# STM32WB55x register map
File version: 1.0
CPU: CM4 r0p1, little endian, 4 interrupt priority bits
Registers are 32-bit, read-write, reset 0x0 unless marked. A register's access mark holds for its fields unless they carry their own. Offsets are from the block's base; [hi:lo] are bit positions; {n}, {i} and the like mark numbered series; 'fields as' and 'values as' point back to an identical list.

## PWR
Base 0x58000400
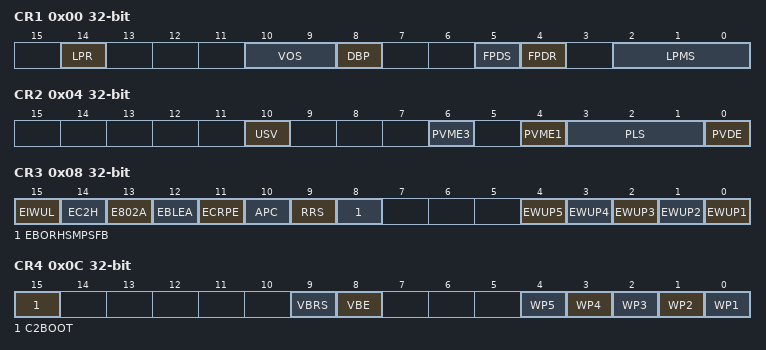
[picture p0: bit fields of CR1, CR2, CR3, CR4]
0x00 CR1
  [14] LPR, [10:9] VOS, [8] DBP, [5] FPDS, [4] FPDR, [2:0] LPMS
0x04 CR2
  [10] USV, [6] PVME3, [4] PVME1, [3:1] PLS, [0] PVDE
0x08 CR3
  [15] EIWUL, [14] EC2H, [13] E802A, [12] EBLEA, [11] ECRPE, [10] APC, [9] RRS, [8] EBORHSMPSFB, [n-1] EWUP{n} (n=1..5)
0x0C CR4
  [15] C2BOOT, [9] VBRS, [8] VBE, [n-1] WP{n} (n=1..5)
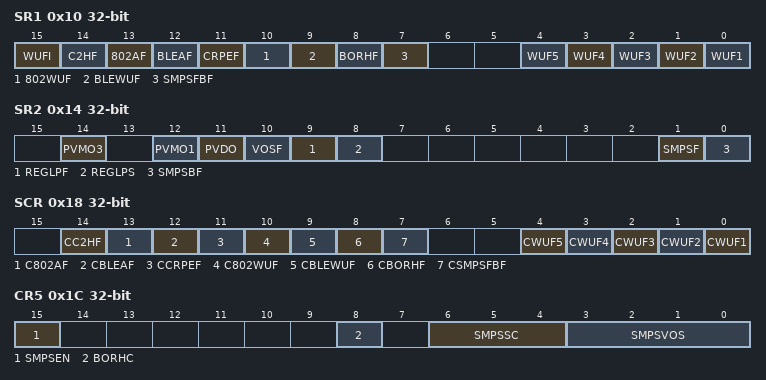
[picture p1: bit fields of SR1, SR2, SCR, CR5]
0x10 SR1
  [15] WUFI, [14] C2HF, [13] 802AF, [12] BLEAF, [11] CRPEF, [10] 802WUF, [9] BLEWUF, [8] BORHF, [7] SMPSFBF, [n-1] WUF{n} (n=1..5)
0x14 SR2
  [14] PVMO3, [12] PVMO1, [11] PVDO, [10] VOSF, [9] REGLPF, [8] REGLPS, [1] SMPSF, [0] SMPSBF
0x18 SCR
  [14] CC2HF, [13] C802AF, [12] CBLEAF, [11] CCRPEF, [10] C802WUF, [9] CBLEWUF, [8] CBORHF, [7] CSMPSFBF, [n-1] CWUF{n} (n=1..5)
0x1C CR5
  [15] SMPSEN, [8] BORHC, [6:4] SMPSSC, [3:0] SMPSVOS
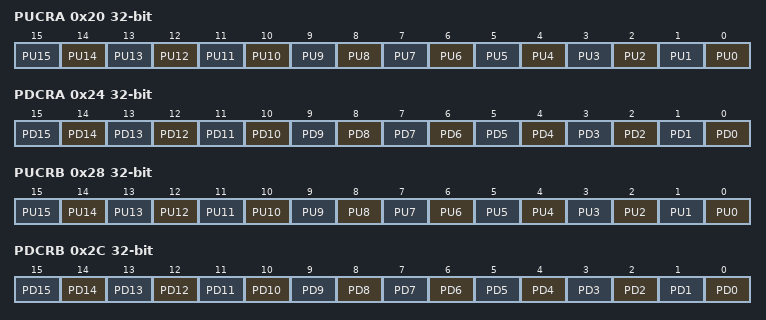
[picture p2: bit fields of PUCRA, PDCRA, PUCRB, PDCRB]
0x20 PUCRA
  [n] PU{n} (n=0..15)
0x24 PDCRA
  [n] PD{n} (n=0..15)
0x28 PUCRB
  [n] PU{n} (n=0..15)
0x2C PDCRB
  [n] PD{n} (n=0..15)
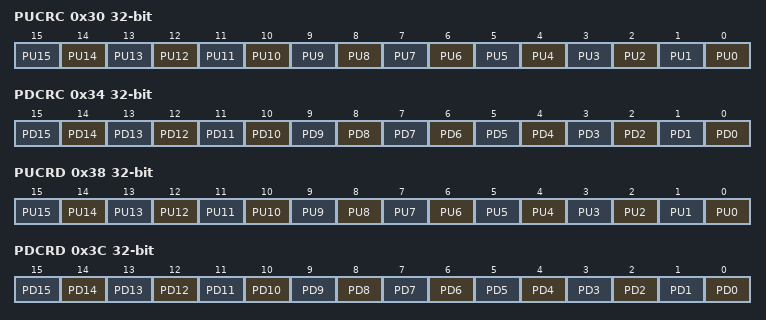
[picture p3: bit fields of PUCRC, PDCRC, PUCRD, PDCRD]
0x30 PUCRC
  [n] PU{n} (n=0..15)
0x34 PDCRC
  [n] PD{n} (n=0..15)
0x38 PUCRD
  [n] PU{n} (n=0..15)
0x3C PDCRD
  [n] PD{n} (n=0..15)
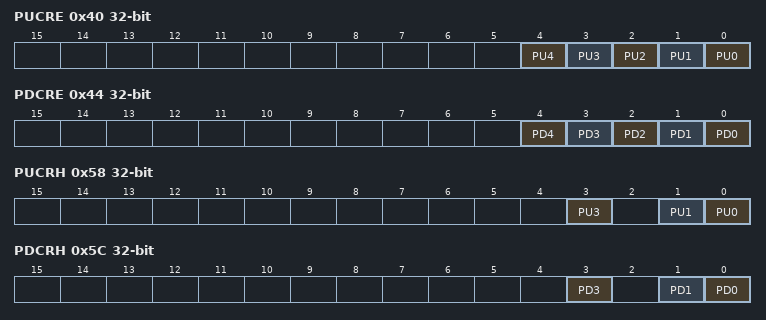
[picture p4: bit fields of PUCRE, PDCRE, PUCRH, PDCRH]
0x40 PUCRE
  [n] PU{n} (n=0..4)
0x44 PDCRE
  [n] PD{n} (n=0..4)
0x58 PUCRH
  [3] PU3, [1] PU1, [0] PU0
0x5C PDCRH
  [3] PD3, [1] PD1, [0] PD0
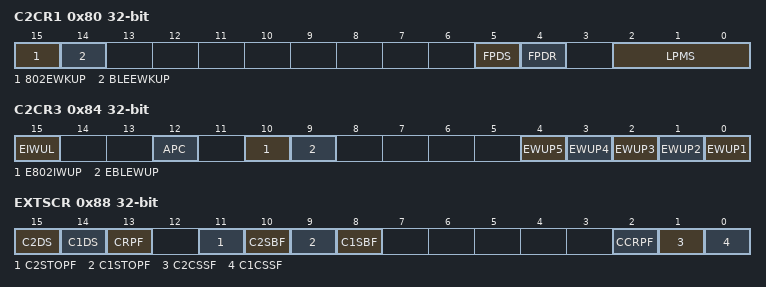
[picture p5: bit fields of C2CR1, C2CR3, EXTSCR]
0x80 C2CR1
  [15] 802EWKUP, [14] BLEEWKUP, [5] FPDS, [4] FPDR, [2:0] LPMS
0x84 C2CR3
  [15] EIWUL, [12] APC, [10] E802IWUP, [9] EBLEWUP, [n-1] EWUP{n} (n=1..5)
0x88 EXTSCR
  [15] C2DS, [14] C1DS, [13] CRPF, [11] C2STOPF, [10] C2SBF, [9] C1STOPF, [8] C1SBF, [2] CCRPF, [1] C2CSSF, [0] C1CSSF

## SAI
Base 0x40015400
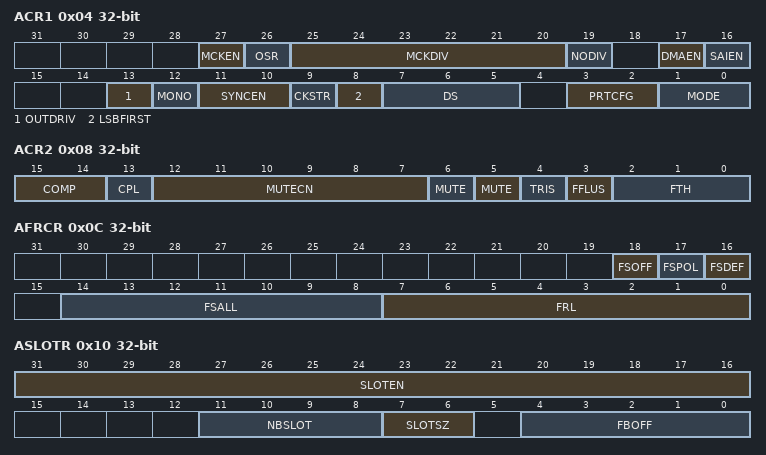
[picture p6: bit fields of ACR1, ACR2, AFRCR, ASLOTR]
0x04 ACR1
  [27] MCKEN, [26] OSR, [25:20] MCKDIV, [19] NODIV, [17] DMAEN, [16] SAIEN, [13] OUTDRIV, [12] MONO, [11:10] SYNCEN, [9] CKSTR, [8] LSBFIRST, [7:5] DS, [3:2] PRTCFG, [1:0] MODE
0x08 ACR2
  [15:14] COMP, [13] CPL, [12:7] MUTECN, [6] MUTE VAL, [5] MUTE, [4] TRIS, [3] FFLUS, [2:0] FTH
0x0C AFRCR
  [18] FSOFF, [17] FSPOL, [16] FSDEF, [14:8] FSALL, [7:0] FRL
0x10 ASLOTR
  [31:16] SLOTEN, [11:8] NBSLOT, [7:6] SLOTSZ, [4:0] FBOFF
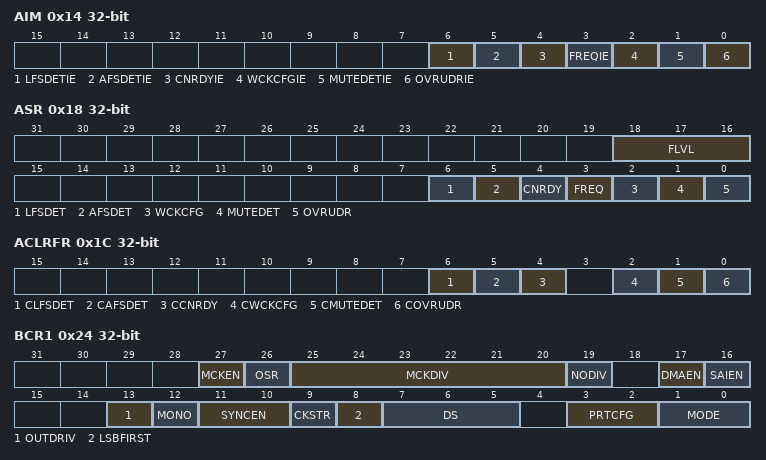
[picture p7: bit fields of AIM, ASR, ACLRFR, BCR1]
0x14 AIM
  [6] LFSDETIE, [5] AFSDETIE, [4] CNRDYIE, [3] FREQIE, [2] WCKCFGIE, [1] MUTEDETIE, [0] OVRUDRIE
0x18 ASR
  [18:16] FLVL, [6] LFSDET, [5] AFSDET, [4] CNRDY, [3] FREQ, [2] WCKCFG, [1] MUTEDET, [0] OVRUDR
0x1C ACLRFR
  [6] CLFSDET, [5] CAFSDET, [4] CCNRDY, [2] CWCKCFG, [1] CMUTEDET, [0] COVRUDR
0x20 ADR
  [31:0] DATA
0x24 BCR1
  fields as ACR1
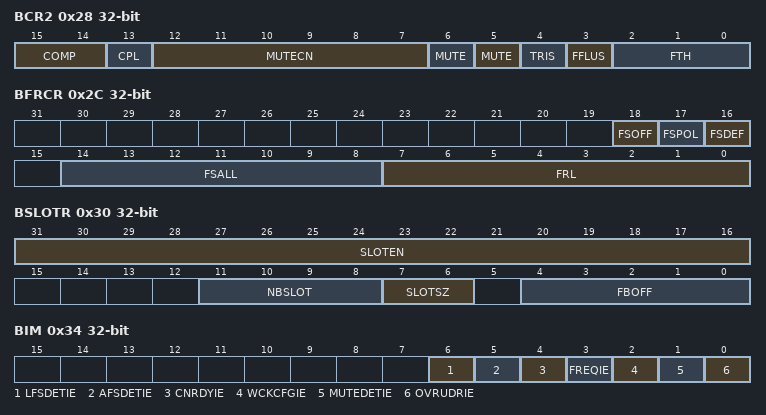
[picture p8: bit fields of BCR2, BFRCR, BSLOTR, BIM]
0x28 BCR2
  fields as ACR2
0x2C BFRCR
  [18] FSOFF, [17] FSPOL, [16] FSDEF, [14:8] FSALL, [7:0] FRL
0x30 BSLOTR
  [31:16] SLOTEN, [11:8] NBSLOT, [7:6] SLOTSZ, [4:0] FBOFF
0x34 BIM
  fields as AIM
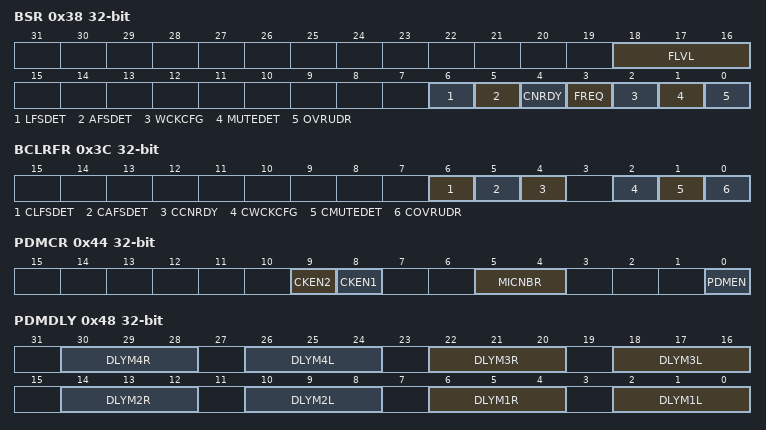
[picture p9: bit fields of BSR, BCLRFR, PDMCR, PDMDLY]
0x38 BSR
  fields as ASR
0x3C BCLRFR
  fields as ACLRFR
0x40 BDR
  [31:0] DATA
0x44 PDMCR
  [9] CKEN2, [8] CKEN1, [5:4] MICNBR, [0] PDMEN
0x48 PDMDLY
  [8n-2:8n-4] DLYM{n}R (n=1..4), [8n-6:8n-8] DLYM{n}L (n=1..4)

## QUADSPI
Base 0xA0001000
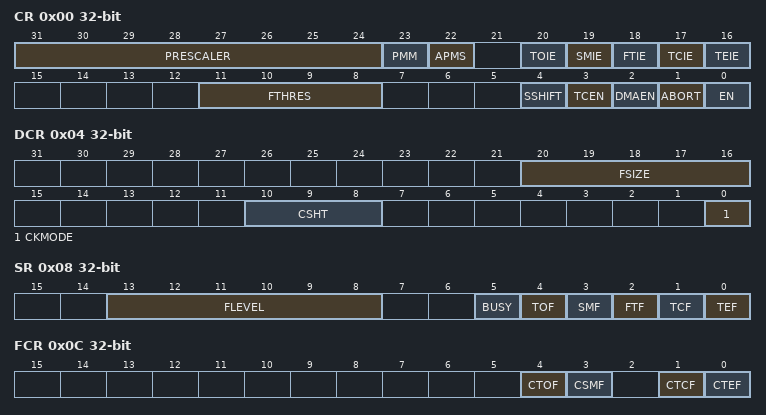
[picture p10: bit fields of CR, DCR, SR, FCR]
0x00 CR
  [31:24] PRESCALER, [23] PMM, [22] APMS, [20] TOIE, [19] SMIE, [18] FTIE, [17] TCIE, [16] TEIE, [11:8] FTHRES, [4] SSHIFT, [3] TCEN, [2] DMAEN, [1] ABORT, [0] EN
0x04 DCR
  [20:16] FSIZE, [10:8] CSHT, [0] CKMODE
0x08 SR
  [13:8] FLEVEL, [5] BUSY, [4] TOF, [3] SMF, [2] FTF, [1] TCF, [0] TEF
0x0C FCR
  [4] CTOF, [3] CSMF, [1] CTCF, [0] CTEF
0x10 DLR
  [31:0] DL
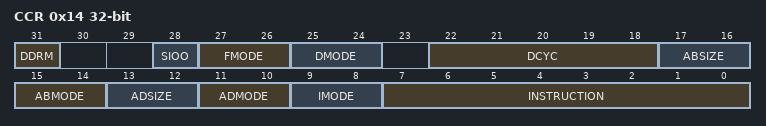
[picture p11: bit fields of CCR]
0x14 CCR
  [31] DDRM, [28] SIOO, [27:26] FMODE, [25:24] DMODE, [22:18] DCYC, [17:16] ABSIZE, [15:14] ABMODE, [13:12] ADSIZE, [11:10] ADMODE, [9:8] IMODE, [7:0] INSTRUCTION
0x18 AR
  [31:0] ADDRESS
0x1C ABR
  [31:0] ALTERNATE
0x20 DR
  [31:0] DATA
0x24 PSMKR
  [31:0] MASK
0x28 PSMAR
  [31:0] MATCH
0x2C PIR
  [15:0] INTERVAL
0x30 LPTR
  [15:0] TIMEOUT

## SYSCFG
Base 0x40010000
0x00 MEMRMP
  [2:0] MEM_MODE
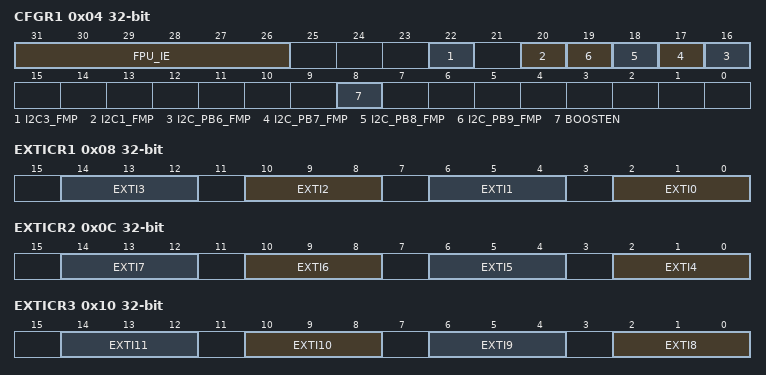
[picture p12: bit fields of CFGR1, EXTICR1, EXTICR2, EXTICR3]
0x04 CFGR1
  [31:26] FPU_IE, [22] I2C3_FMP, [20] I2C1_FMP, [n+10] I2C_PB{n}_FMP (n=6..9), [8] BOOSTEN
0x08 EXTICR1
  [4n+2:4n] EXTI{n} (n=0..3)
0x0C EXTICR2
  [4n-14:4n-16] EXTI{n} (n=4..7)
0x10 EXTICR3
  [4n-30:4n-32] EXTI{n} (n=8..11)
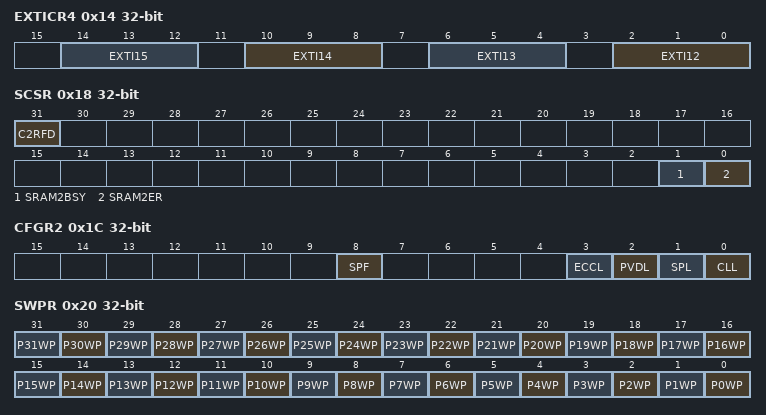
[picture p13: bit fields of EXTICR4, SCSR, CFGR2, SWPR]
0x14 EXTICR4
  [4n-46:4n-48] EXTI{n} (n=12..15)
0x18 SCSR
  [31] C2RFD, [1] SRAM2BSY, [0] SRAM2ER
0x1C CFGR2
  [8] SPF, [3] ECCL, [2] PVDL, [1] SPL, [0] CLL
0x20 SWPR
  [n] P{n}WP (n=0..31)
0x24 SKR
  [7:0] KEY
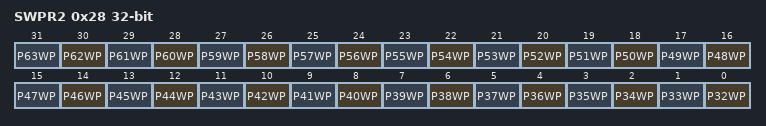
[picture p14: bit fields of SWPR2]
0x28 SWPR2
  [n-32] P{n}WP (n=32..63)
